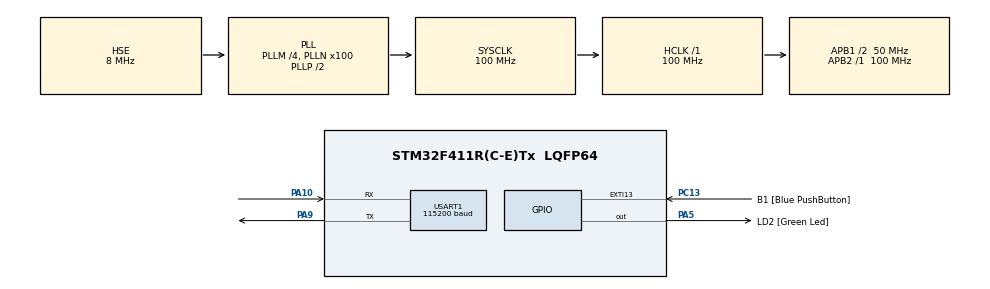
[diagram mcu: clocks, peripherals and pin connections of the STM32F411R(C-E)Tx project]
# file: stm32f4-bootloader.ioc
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Mcu.Family=STM32F4
Mcu.Name=STM32F411R(C-E)Tx
Mcu.Package=LQFP64
NVIC.PriorityGroup=NVIC_PRIORITYGROUP_0
NVIC.TIM2_IRQn=true\:0\:0\:false\:false\:true\:false\:true
NVIC.TimeBase=TIM2_IRQn
NVIC.TimeBaseIP=TIM2
PA10.Mode=Asynchronous
PA10.Signal=USART1_RX
PA13.GPIO_Label=TMS
PA13.Mode=Serial_Wire
PA13.Signal=SYS_JTMS-SWDIO
PA14.GPIO_Label=TCK
PA14.Mode=Serial_Wire
PA14.Signal=SYS_JTCK-SWCLK
PA5.GPIO_Label=LD2 [Green Led]
PA5.Signal=GPIO_Output
PA9.Mode=Asynchronous
PA9.Signal=USART1_TX
PB3.GPIO_Label=SWO
PB3.Signal=SYS_JTDO-SWO
PC13-ANTI_TAMP.GPIO_Label=B1 [Blue PushButton]
PC13-ANTI_TAMP.GPIO_ModeDefaultEXTI=GPIO_MODE_IT_FALLING
PC13-ANTI_TAMP.Signal=GPXTI13
PC14-OSC32_IN.Signal=RCC_OSC32_IN
PC15-OSC32_OUT.Signal=RCC_OSC32_OUT
PH0\ -\ OSC_IN.Mode=HSE-External-Oscillator
PH0\ -\ OSC_IN.Signal=RCC_OSC_IN
PH1\ -\ OSC_OUT.Mode=HSE-External-Oscillator
PH1\ -\ OSC_OUT.Signal=RCC_OSC_OUT
ProjectManager.HeapSize=0x200
ProjectManager.StackSize=0x400
ProjectManager.TargetToolchain=Makefile
RCC.48MHZClocksFreq_Value=50000000
RCC.AHBFreq_Value=100000000
RCC.APB1CLKDivider=RCC_HCLK_DIV2
RCC.APB1Freq_Value=50000000
RCC.APB1TimFreq_Value=100000000
RCC.APB2Freq_Value=100000000
RCC.APB2TimFreq_Value=100000000
RCC.CortexFreq_Value=100000000
RCC.FLatency-AdvancedSettings=FLASH_LATENCY_3
RCC.HCLKFreq_Value=100000000
RCC.HSE_VALUE=8000000
RCC.HSI_VALUE=16000000
RCC.LSE_VALUE=32768
RCC.PLLM=4
RCC.PLLN=100
RCC.PLLSourceVirtual=RCC_PLLSOURCE_HSE
RCC.SYSCLKFreq_VALUE=100000000
RCC.SYSCLKSource=RCC_SYSCLKSOURCE_PLLCLK
RCC.VCOOutputFreq_Value=200000000
USART1.BaudRate=115200
USART1.VirtualMode=VM_ASYNC
VP_SYS_VS_tim2.Mode=TIM2
board=NUCLEO-F411RE

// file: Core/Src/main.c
/* USER CODE BEGIN Header */
/**
  ******************************************************************************
  * @file           : main.c
  * @brief          : Main program body
  ******************************************************************************
  * @attention
  *
  * <h2><center>&copy; Copyright (c) 2020 STMicroelectronics.
  * All rights reserved.</center></h2>
  *
  * This software component is licensed by ST under BSD 3-Clause license,
  * the "License"; You may not use this file except in compliance with the
  * License. You may obtain a copy of the License at:
  *                        opensource.org/licenses/BSD-3-Clause
  *
  ******************************************************************************
  */
/* USER CODE END Header */
#include "main.h"

/* USER CODE BEGIN Includes */
#include "uart.h"
#include "config.h"
#include "flash.h"
#include "xmodem.h"
/* USER CODE END Includes */

UART_HandleTypeDef huart1;

void SystemClock_Config(void);
static void MX_GPIO_Init(void);
static void MX_USART1_UART_Init(void);

int main(void)
{

  /* MCU Configuration--------------------------------------------------------*/

  /* Reset of all peripherals, Initializes the Flash interface and the Systick. */
  HAL_Init();

  /* Configure the system clock */
  SystemClock_Config();

  /* Initialize all configured peripherals */
  MX_GPIO_Init();
  MX_USART1_UART_Init();
  /* USER CODE BEGIN 2 */
  uart_transmit_ch(7); // Transmit BEL character
  // Handle "flashfw" command
  uint8_t resp = 0;

  // Check if the reponse was an ACK character
  if(uart_receive(&resp, 1) == UART_OK) {
	  if(resp == 6) {
		  uart_transmit_str((uint8_t *)(MCU_TYPE));
		  if(uart_receive(&resp, 1) == UART_OK) {
			  if(resp == 6) {
//				  uart_transmit_str((uint8_t *)("Flashing firmware!"));
				  xmodem_receive();
			  }
		  }
	  }
  }
  flash_jump_to_app();
  /* USER CODE END 2 */

  /* Infinite loop */
  while (1)
  {

  }
}

#ifdef STM32F411xE
void SystemClock_Config(void)
{
  RCC_OscInitTypeDef RCC_OscInitStruct = {0};
  RCC_ClkInitTypeDef RCC_ClkInitStruct = {0};

  /** Configure the main internal regulator output voltage
  */
  __HAL_RCC_PWR_CLK_ENABLE();
  __HAL_PWR_VOLTAGESCALING_CONFIG(PWR_REGULATOR_VOLTAGE_SCALE1);
  /** Initializes the RCC Oscillators according to the specified parameters
  * in the RCC_OscInitTypeDef structure.
  */
  RCC_OscInitStruct.OscillatorType = RCC_OSCILLATORTYPE_HSE;
  RCC_OscInitStruct.HSEState = RCC_HSE_ON;
  RCC_OscInitStruct.PLL.PLLState = RCC_PLL_ON;
  RCC_OscInitStruct.PLL.PLLSource = RCC_PLLSOURCE_HSE;
  RCC_OscInitStruct.PLL.PLLM = 4;
  RCC_OscInitStruct.PLL.PLLN = 100;
  RCC_OscInitStruct.PLL.PLLP = RCC_PLLP_DIV2;
  RCC_OscInitStruct.PLL.PLLQ = 4;
  if (HAL_RCC_OscConfig(&RCC_OscInitStruct) != HAL_OK)
  {
    Error_Handler();
  }
  /** Initializes the CPU, AHB and APB buses clocks
  */
  RCC_ClkInitStruct.ClockType = RCC_CLOCKTYPE_HCLK|RCC_CLOCKTYPE_SYSCLK
                              |RCC_CLOCKTYPE_PCLK1|RCC_CLOCKTYPE_PCLK2;
  RCC_ClkInitStruct.SYSCLKSource = RCC_SYSCLKSOURCE_PLLCLK;
  RCC_ClkInitStruct.AHBCLKDivider = RCC_SYSCLK_DIV1;
  RCC_ClkInitStruct.APB1CLKDivider = RCC_HCLK_DIV2;
  RCC_ClkInitStruct.APB2CLKDivider = RCC_HCLK_DIV1;

  if (HAL_RCC_ClockConfig(&RCC_ClkInitStruct, FLASH_LATENCY_3) != HAL_OK)
  {
    Error_Handler();
  }
}
#endif

#ifdef STM32F446xx
void SystemClock_Config(void)
{
  RCC_OscInitTypeDef RCC_OscInitStruct = {0};
  RCC_ClkInitTypeDef RCC_ClkInitStruct = {0};

  /** Configure the main internal regulator output voltage
  */
  __HAL_RCC_PWR_CLK_ENABLE();
  __HAL_PWR_VOLTAGESCALING_CONFIG(PWR_REGULATOR_VOLTAGE_SCALE1);
  /** Initializes the RCC Oscillators according to the specified parameters
  * in the RCC_OscInitTypeDef structure.
  */
  RCC_OscInitStruct.OscillatorType = RCC_OSCILLATORTYPE_HSE;
  RCC_OscInitStruct.HSEState = RCC_HSE_ON;
  RCC_OscInitStruct.PLL.PLLState = RCC_PLL_ON;
  RCC_OscInitStruct.PLL.PLLSource = RCC_PLLSOURCE_HSE;
  RCC_OscInitStruct.PLL.PLLM = 4;
  RCC_OscInitStruct.PLL.PLLN = 180;
  RCC_OscInitStruct.PLL.PLLP = RCC_PLLP_DIV2;
  RCC_OscInitStruct.PLL.PLLQ = 7;
  RCC_OscInitStruct.PLL.PLLR = 2;
  if (HAL_RCC_OscConfig(&RCC_OscInitStruct) != HAL_OK)
  {
    Error_Handler();
  }
  /** Activate the Over-Drive mode
  */
  if (HAL_PWREx_EnableOverDrive() != HAL_OK)
  {
    Error_Handler();
  }
  /** Initializes the CPU, AHB and APB buses clocks
  */
  RCC_ClkInitStruct.ClockType = RCC_CLOCKTYPE_HCLK|RCC_CLOCKTYPE_SYSCLK
                              |RCC_CLOCKTYPE_PCLK1|RCC_CLOCKTYPE_PCLK2;
  RCC_ClkInitStruct.SYSCLKSource = RCC_SYSCLKSOURCE_PLLRCLK;
  RCC_ClkInitStruct.AHBCLKDivider = RCC_SYSCLK_DIV1;
  RCC_ClkInitStruct.APB1CLKDivider = RCC_HCLK_DIV4;
  RCC_ClkInitStruct.APB2CLKDivider = RCC_HCLK_DIV2;

  if (HAL_RCC_ClockConfig(&RCC_ClkInitStruct, FLASH_LATENCY_5) != HAL_OK)
  {
    Error_Handler();
  }
}
#endif

static void MX_USART1_UART_Init(void)
{

  huart1.Instance = USART1;
  huart1.Init.BaudRate = 250000;
  huart1.Init.WordLength = UART_WORDLENGTH_8B;
  huart1.Init.StopBits = UART_STOPBITS_1;
  huart1.Init.Parity = UART_PARITY_NONE;
  huart1.Init.Mode = UART_MODE_TX_RX;
  huart1.Init.HwFlowCtl = UART_HWCONTROL_NONE;
  huart1.Init.OverSampling = UART_OVERSAMPLING_16;
  if (HAL_UART_Init(&huart1) != HAL_OK)
  {
    Error_Handler();
  }

}

static void MX_GPIO_Init(void)
{
  GPIO_InitTypeDef GPIO_InitStruct = {0};

  /* GPIO Ports Clock Enable */
  __HAL_RCC_GPIOC_CLK_ENABLE();
  __HAL_RCC_GPIOH_CLK_ENABLE();
  __HAL_RCC_GPIOA_CLK_ENABLE();
  __HAL_RCC_GPIOB_CLK_ENABLE();

  /*Configure GPIO pin Output Level */
  HAL_GPIO_WritePin(LD2_GPIO_Port, LD2_Pin, GPIO_PIN_RESET);

  /*Configure GPIO pin : B1_Pin */
  GPIO_InitStruct.Pin = B1_Pin;
  GPIO_InitStruct.Mode = GPIO_MODE_IT_FALLING;
  GPIO_InitStruct.Pull = GPIO_NOPULL;
  HAL_GPIO_Init(B1_GPIO_Port, &GPIO_InitStruct);

  /*Configure GPIO pin : LD2_Pin */
  GPIO_InitStruct.Pin = LD2_Pin;
  GPIO_InitStruct.Mode = GPIO_MODE_OUTPUT_PP;
  GPIO_InitStruct.Pull = GPIO_NOPULL;
  GPIO_InitStruct.Speed = GPIO_SPEED_FREQ_LOW;
  HAL_GPIO_Init(LD2_GPIO_Port, &GPIO_InitStruct);

}

void HAL_TIM_PeriodElapsedCallback(TIM_HandleTypeDef *htim)
{
  if (htim->Instance == TIM2) {
    HAL_IncTick();
  }
}

void Error_Handler(void)
{
}

/************************ (C) COPYRIGHT STMicroelectronics *****END OF FILE****/
